VERSION ""

NS_ :

BS_:

BU_: XXX

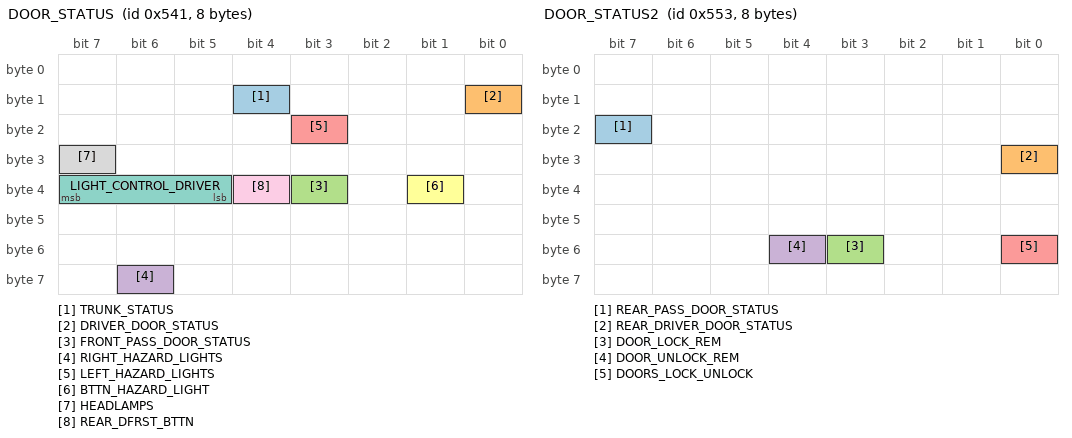
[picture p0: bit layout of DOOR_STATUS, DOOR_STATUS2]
BO_ 1345 DOOR_STATUS: 8 XXX
 SG_ TRUNK_STATUS : 12|1@0+ (1,0) [0|1] "" XXX
 SG_ DRIVER_DOOR_STATUS : 8|1@0+ (1,0) [0|1] "" XXX
 SG_ FRONT_PASS_DOOR_STATUS : 35|1@0+ (1,0) [0|1] "" XXX
 SG_ RIGHT_HAZARD_LIGHTS : 62|1@0+ (1,0) [0|1] "" XXX
 SG_ LEFT_HAZARD_LIGHTS : 19|1@0+ (1,0) [0|1] "" XXX
 SG_ BTTN_HAZARD_LIGHT : 33|1@0+ (1,0) [0|1] "" XXX
 SG_ LIGHT_CONTROL_DRIVER : 39|3@0+ (1,0) [0|7] "" XXX
 SG_ HEADLAMPS : 31|1@0+ (1,0) [0|1] "" XXX
 SG_ REAR_DFRST_BTTN : 36|1@0+ (1,0) [0|1] "" XXX

BO_ 339 undefined: 8 XXX

BO_ 1363 DOOR_STATUS2: 8 XXX
 SG_ REAR_PASS_DOOR_STATUS : 23|1@0+ (1,0) [0|1] "" XXX
 SG_ REAR_DRIVER_DOOR_STATUS : 24|1@0+ (1,0) [0|1] "" XXX
 SG_ DOOR_LOCK_REM : 51|1@0+ (1,0) [0|1] "" XXX
 SG_ DOOR_UNLOCK_REM : 52|1@0+ (1,0) [0|1] "" XXX
 SG_ DOORS_LOCK_UNLOCK : 48|1@0+ (1,0) [0|1] "" XXX

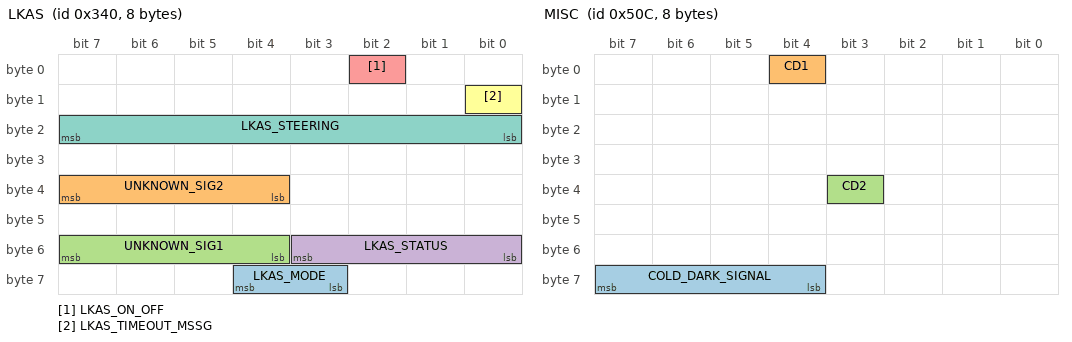
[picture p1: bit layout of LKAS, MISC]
BO_ 832 LKAS: 8 XXX
 SG_ LKAS_MODE : 60|2@0+ (1,0) [0|3] "" XXX
 SG_ UNKNOWN_SIG2 : 36|4@1- (1,0) [0|15] "" XXX
 SG_ UNKNOWN_SIG1 : 55|4@0+ (1,0) [0|15] "" XXX
 SG_ LKAS_STATUS : 48|4@1+ (1,0) [0|15] "" XXX
 SG_ LKAS_ON_OFF : 2|1@0+ (1,0) [0|1] "" XXX
 SG_ LKAS_TIMEOUT_MSSG : 8|1@0+ (1,0) [0|1] "" XXX
 SG_ LKAS_STEERING : 23|8@0- (1,0) [0|255] "" XXX

BO_ 1292 MISC: 8 XXX
 SG_ COLD_DARK_SIGNAL : 63|4@0+ (1,0) [0|15] "" XXX
 SG_ CD1 : 4|1@0+ (1,0) [0|1] "" XXX
 SG_ CD2 : 35|1@0+ (1,0) [0|1] "" XXX

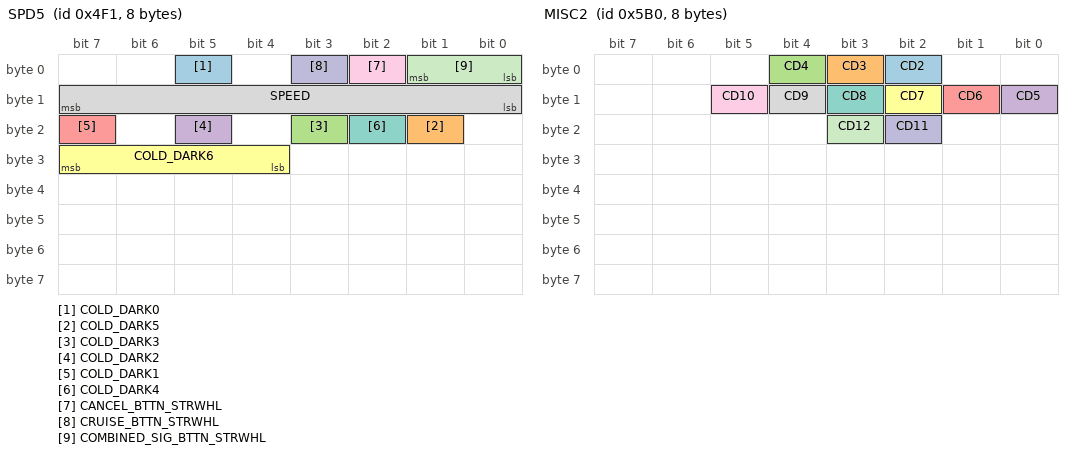
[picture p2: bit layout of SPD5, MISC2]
BO_ 1265 SPD5: 8 XXX
 SG_ COLD_DARK0 : 5|1@0+ (1,0) [0|1] "" XXX
 SG_ COLD_DARK5 : 17|1@0+ (1,0) [0|1] "" XXX
 SG_ COLD_DARK3 : 19|1@0+ (1,0) [0|1] "" XXX
 SG_ COLD_DARK2 : 21|1@0+ (1,0) [0|1] "" XXX
 SG_ COLD_DARK1 : 23|1@0+ (1,0) [0|1] "" XXX
 SG_ COLD_DARK6 : 31|4@0- (1,0) [0|15] "" XXX
 SG_ COLD_DARK4 : 18|1@0+ (1,0) [0|1] "" XXX
 SG_ SPEED : 15|8@0+ (1,0) [0|255] "" XXX
 SG_ CANCEL_BTTN_STRWHL : 2|1@0+ (1,0) [0|1] "" XXX
 SG_ CRUISE_BTTN_STRWHL : 3|1@0+ (1,0) [0|1] "" XXX
 SG_ COMBINED_SIG_BTTN_STRWHL : 0|2@1+ (1,0) [0|3] "" XXX

BO_ 1456 MISC2: 8 XXX
 SG_ CD2 : 2|1@0+ (1,0) [0|1] "" XXX
 SG_ CD3 : 3|1@0+ (1,0) [0|1] "" XXX
 SG_ CD4 : 4|1@0+ (1,0) [0|1] "" XXX
 SG_ CD5 : 8|1@0+ (1,0) [0|1] "" XXX
 SG_ CD6 : 9|1@0+ (1,0) [0|1] "" XXX
 SG_ CD7 : 10|1@0+ (1,0) [0|1] "" XXX
 SG_ CD8 : 11|1@0+ (1,0) [0|1] "" XXX
 SG_ CD9 : 12|1@0+ (1,0) [0|1] "" XXX
 SG_ CD10 : 13|1@0+ (1,0) [0|1] "" XXX
 SG_ CD11 : 18|1@0+ (1,0) [0|1] "" XXX
 SG_ CD12 : 19|1@0+ (1,0) [0|1] "" XXX

BO_ 1407 undefined: 8 XXX

BO_ 1491 MISC3: 8 XXX
 SG_ CD1 : 7|8@0+ (1,0) [0|255] "" XXX

BO_ 1472 undefined: 8 XXX

BO_ 1294 undefined: 8 XXX

BO_ 1314 undefined: 8 XXX

BO_ 1369 undefined: 8 XXX

BO_ 1427 undefined: 8 XXX

BO_ 1322 SPD4: 8 XXX
 SG_ SPEED : 7|8@0+ (1,0) [0|255] "" XXX

BO_ 127 undefined: 8 XXX

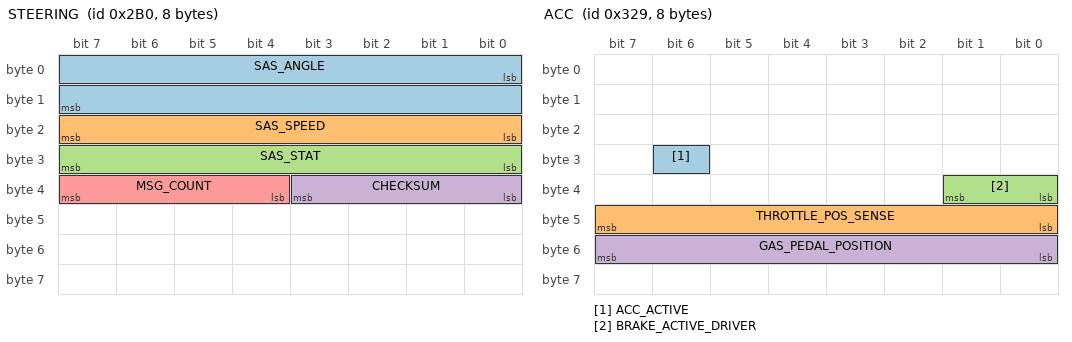
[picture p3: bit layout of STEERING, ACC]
BO_ 688 STEERING: 8 XXX
 SG_ SAS_ANGLE : 0|16@1- (1,0) [0|65535] "" XXX
 SG_ SAS_SPEED : 23|8@0+ (1,0) [0|255] "" XXX
 SG_ SAS_STAT : 31|8@0+ (1,0) [0|255] "" XXX
 SG_ CHECKSUM : 32|4@1+ (1,0) [0|15] "" XXX
 SG_ MSG_COUNT : 39|4@0+ (1,0) [0|15] "" XXX

BO_ 809 ACC: 8 XXX
 SG_ ACC_ACTIVE : 30|1@0+ (1,0) [0|1] "" XXX
 SG_ THROTTLE_POS_SENSE : 47|8@0+ (1,0) [0|255] "" XXX
 SG_ BRAKE_ACTIVE_DRIVER : 32|2@1+ (1,0) [0|3] "" XXX
 SG_ GAS_PEDAL_POSITION : 55|8@0+ (1,0) [0|255] "" XXX

BO_ 273 SPD0: 8 XXX
 SG_ SPEED : 55|8@0+ (1,0) [0|255] "" XXX
 SG_ GEAR_POSITION : 8|3@1+ (1,0) [0|7] "" XXX

BO_ 274 SPD1: 8 XXX
 SG_ SPEED1 : 55|8@0+ (1,0) [0|255] "" XXX
 SG_ SPEED : 23|8@0+ (1,0) [0|255] "" XXX

BO_ 790 SPD2: 8 XXX
 SG_ SPEED1 : 55|8@0+ (1,0) [0|255] "" XXX
 SG_ SPEED : 31|8@0+ (1,0) [0|255] "" XXX

BO_ 1366 SPD3: 8 XXX
 SG_ SPEED1 : 39|8@0+ (1,0) [0|255] "" XXX
 SG_ SPEED : 31|8@0+ (1,0) [0|255] "" XXX

BO_ 275 MOVE_OP: 8 XXX
 SG_ REVERSE_SIGNAL_UNKWN : 23|3@0+ (1,0) [0|7] "" XXX

BO_ 916 BRAKE_LIGHT: 8 XXX
 SG_ BRAKE_LIGHT1 : 46|1@0+ (1,0) [0|1] "" XXX
 SG_ BRAKE_LIGHT2 : 55|1@0+ (1,0) [0|1] "" XXX

BO_ 608 PEDAL_POSITION: 8 XXX

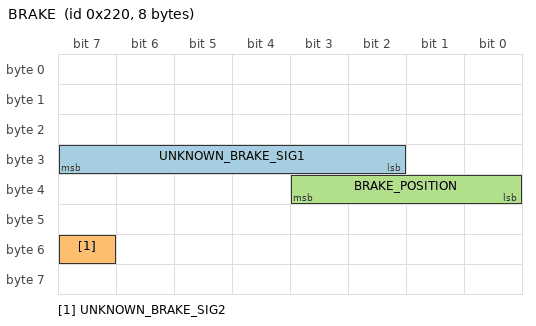
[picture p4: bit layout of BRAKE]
BO_ 544 BRAKE: 8 XXX
 SG_ UNKNOWN_BRAKE_SIG1 : 31|6@0+ (1,0) [0|63] "" XXX
 SG_ UNKNOWN_BRAKE_SIG2 : 55|1@0+ (1,0) [0|1] "" XXX
 SG_ BRAKE_POSITION : 32|4@1+ (1,0) [0|15] "" XXX

CM_ SG_ 1345 LIGHT_CONTROL_DRIVER "Auto= 111 DRL= 010 On = 100";
CM_ SG_ 1345 REAR_DFRST_BTTN "On when rear defrost button is on";
CM_ SG_ 1363 DOORS_LOCK_UNLOCK "Remote signal from FOB";
CM_ SG_ 832 LKAS_MODE "01=LDW 10=STNRD LKA 11=Active LKA";
CM_ SG_ 832 LKAS_TIMEOUT_MSSG "3rd byte initially add 4th looked like incomplete signal";
CM_ SG_ 832 LKAS_STEERING "neg= right pos= left Maybe separate signals?";
CM_ SG_ 1292 COLD_DARK_SIGNAL "Signal Active when in proximity to vehicle during cold and dark state - Doors Locked";
CM_ SG_ 1292 CD1 "Signal Active when in proximity to vehicle during cold and dark state - Doors Locked";
CM_ SG_ 1292 CD2 "Signal Active when in proximity to vehicle during cold and dark state - Doors Locked";
CM_ SG_ 1265 COLD_DARK0 "Signal Active when in proximity to vehicle during cold and dark state - Doors Locked";
CM_ SG_ 1265 COLD_DARK5 "Signal Active when in proximity to vehicle during cold and dark state - Doors Locked";
CM_ SG_ 1265 COLD_DARK3 "Signal Active when in proximity to vehicle during cold and dark state - Doors Locked";
CM_ SG_ 1265 COLD_DARK2 "Signal Active when in proximity to vehicle during cold and dark state - Doors Locked";
CM_ SG_ 1265 COLD_DARK1 "Signal Active when in proximity to vehicle during cold and dark state - Doors Locked";
CM_ SG_ 1265 COLD_DARK6 "Signal Active when in proximity to vehicle during cold and dark state - Doors Locked";
CM_ SG_ 1265 COLD_DARK4 "Signal Active when in proximity to vehicle during cold and dark state - Doors Locked";
CM_ SG_ 1265 COMBINED_SIG_BTTN_STRWHL "01 = RES + 10= SET - 11= DIS BTTN";
CM_ SG_ 688 SAS_SPEED "Borrowed Byte Location from i30_2014.dbc";
CM_ SG_ 688 SAS_STAT "Borrowed Byte Location from i30_2014.dbc";
CM_ SG_ 688 CHECKSUM "Borrowed Byte Location from i30_2014.dbc";
CM_ SG_ 688 MSG_COUNT "Borrowed Byte Location from i30_2014.dbc";
CM_ SG_ 809 BRAKE_ACTIVE_DRIVER "01= No driver input 10= driver input";
CM_ SG_ 273 GEAR_POSITION "P=000 R=111 N=110 D=101";
CM_ SG_ 544 BRAKE_POSITION "Not 100% on this but it matches";
VAL_ 1345 LIGHT_CONTROL_DRIVER 7 "Auto" 4 "On" 2 "DRL" ;
